# MKL28T7_CORE1 register map
Vendor: Freescale Semiconductor, Inc.; Series: Kinetis_L; File version: 1.6
CPU: CM0PLUS r0p0, little endian, no MPU, no FPU, VTOR, 2 interrupt priority bits
Registers are 32-bit, read-write, reset 0x0 unless marked. A register's access mark holds for its fields unless they carry their own. Offsets are from the block's base; [hi:lo] are bit positions; {n}, {i} and the like mark numbered series.

## MTB0 — Micro Trace Buffer
Base 0xF0000000; register names take the prefix MTB0_
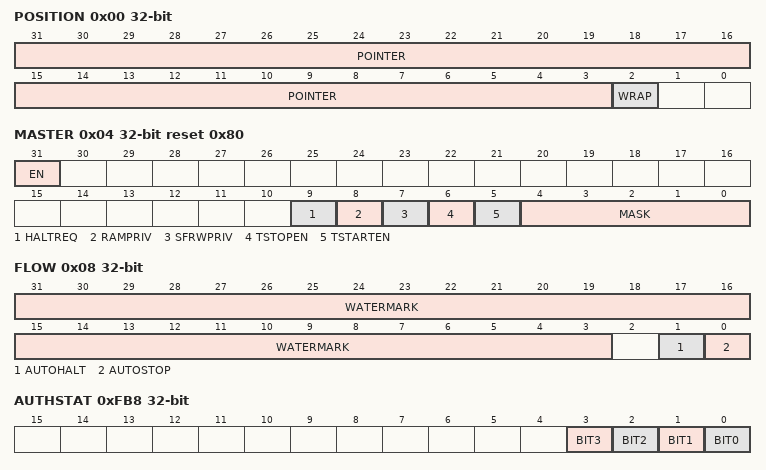
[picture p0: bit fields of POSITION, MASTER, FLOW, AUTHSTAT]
0x00 POSITION (reset mask 0x3) — MTB Position Register
  [31:3] POINTER — Trace Packet Address Pointer[28:0]
  [2] WRAP
0x04 MASTER reset 0x80 (reset mask 0xFFFFFFE0) — MTB Master Register
  [31] EN — Main Trace Enable
  [9] HALTREQ — Halt Request
  [8] RAMPRIV — RAM Privilege
  [7] SFRWPRIV — Special Function Register Write Privilege
  [6] TSTOPEN — Trace Stop Input Enable
  [5] TSTARTEN — Trace Start Input Enable
  [4:0] MASK
0x08 FLOW (reset mask 0x4) — MTB Flow Register
  [31:3] WATERMARK — WATERMARK[28:0]
  [1] AUTOHALT
  [0] AUTOSTOP
0x0C BASE ro reset not defined — MTB Base Register
  [31:0] BASEADDR
0xF00 MODECTRL ro — Integration Mode Control Register
0xFA0 TAGSET ro — Claim TAG Set Register
0xFA4 TAGCLEAR ro — Claim TAG Clear Register
0xFB0 LOCKACCESS ro
  [31:0] LOCKACCESS — Hardwired to 0x0000_0000
0xFB4 LOCKSTAT ro — Lock Status Register
0xFB8 AUTHSTAT ro — Authentication Status Register
  [3] BIT3
  [2] BIT2
  [1] BIT1
  [0] BIT0 — Connected to DBGEN.
0xFBC DEVICEARCH ro reset 0x47700A31 — Device Architecture Register
0xFC8 DEVICECFG ro — Device Configuration Register
0xFCC DEVICETYPID ro reset 0x31 — Device Type Identifier Register
0xFD0 PERIPHID{x} (x=4,5,6,7,0,1,2,3; step 0x4) ro reset not defined — Peripheral ID Register
  [31:0] PERIPHID
{0xFF0+4i} COMPID{i} (i=0..3) ro reset not defined — Component ID Register
  [31:0] COMPID — Component ID

## MTB1 — Micro Trace Buffer
Base 0xF1000000; register names take the prefix MTB1_
Registers as MTB0.

## MCM0 — Core Platform Miscellaneous Control Module
Base 0xF0003000; register names take the prefix MCM0_
0x08 PLASC 16-bit ro reset 0xF — Crossbar Switch (AXBS) Slave Configuration
  [7:0] ASC — Each bit in the ASC field indicates whether there is a corresponding connection to the crossbar switch's slave input port.
    0=A bus slave connection to AXBS input port n is absent; 1=A bus slave connection to AXBS input port n is present
0x0A PLAMC 16-bit ro reset 0xF — Crossbar Switch (AXBS) Master Configuration
  [7:0] AMC — Each bit in the AMC field indicates whether there is a corresponding connection to the AXBS master input port.
    0=A bus master connection to AXBS input port n is absent; 1=A bus master connection to AXBS input port n is present
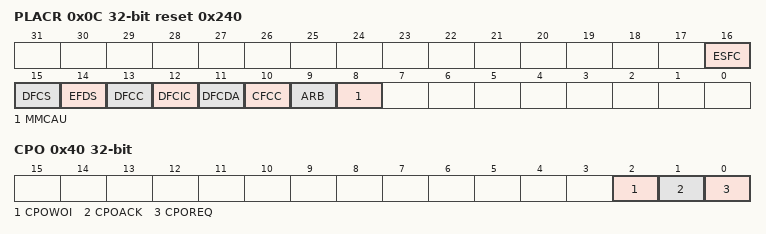
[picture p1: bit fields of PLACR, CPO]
0x0C PLACR reset 0x240 — Platform Control Register
  [16] ESFC — Enable Stalling Flash Controller
    0=Disable stalling flash controller when flash is busy; 1=Enable stalling flash controller when flash is busy
  [15] DFCS — Disable Flash Controller Speculation
    0=Enable flash controller speculation; 1=Disable flash controller speculation
  [14] EFDS — Enable Flash Data Speculation
    0=Disable flash data speculation; 1=Enable flash data speculation
  [13] DFCC — Disable Flash Controller Cache
    0=Enable flash controller cache; 1=Disable flash controller cache
  [12] DFCIC — Disable Flash Controller Instruction Caching
    0=Enable flash controller instruction caching; 1=Disable flash controller instruction caching
  [11] DFCDA — Disable Flash Controller Data Caching
    0=Enable flash controller data caching; 1=Disable flash controller data caching
  [10] CFCC wo — Clear Flash Controller Cache
  [9] ARB — Arbitration select
    0=Fixed-priority arbitration for the crossbar masters; 1=Round-robin arbitration for the crossbar masters
  [8] MMCAU ro — MMCAU Present
    0=MMCAU is disabled; 1=MMCAU is enabled
0x40 CPO — Compute Operation Control Register
  [2] CPOWOI — Compute Operation Wake-up on Interrupt
    0=No effect; 1=When set, the CPOREQ is cleared on any interrupt or exception vector fetch
  [1] CPOACK ro — Compute Operation Acknowledge
    0=Compute operation entry has not completed or compute operation exit has completed; 1=Compute operation entry has completed or compute operation exit has not completed
  [0] CPOREQ — Compute Operation Request
    0=Request is cleared; 1=Request Compute Operation

## MCM1 — Core Platform Miscellaneous Control Module
Base 0xF1003000; register names take the prefix MCM1_
Registers as MCM0.
